# STM32WL5x_CM0P register map
File version: 1.5
CPU: CM0 r0p1, little endian, MPU, no FPU, 4 interrupt priority bits
Registers are 32-bit, read-write, reset 0x0 unless marked. A register's access mark holds for its fields unless they carry their own. Offsets are from the block's base; [hi:lo] are bit positions; {n}, {i} and the like mark numbered series; 'fields as' and 'values as' point back to an identical list.

## DMA1 — Direct memory access controller
Base 0x40020000
Same registers: DMA2 0x40020400
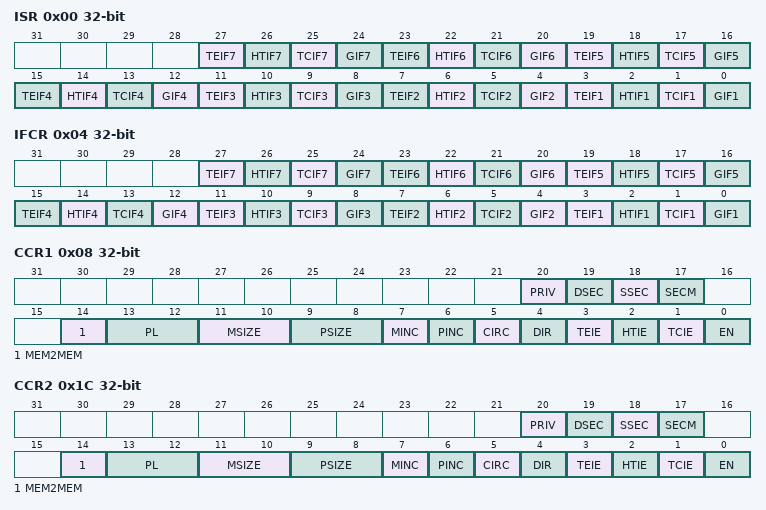
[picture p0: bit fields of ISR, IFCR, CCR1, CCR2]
0x00 ISR ro — interrupt status register
  [4n-1] TEIF{n} (n=1..7) — transfer error (TE) flag for channel {n}
  [4n-2] HTIF{n} (n=1..7) — half transfer (HT) flag for channel {n}
  [4n-3] TCIF{n} (n=1..7) — transfer complete (TC) flag for channel {n}
  [4n-4] GIF{n} (n=1..7) — global interrupt flag for channel {n}
0x04 IFCR wo — interrupt flag clear register
  [4n-1] TEIF{n} (n=1..7) — transfer error flag clear for channel {n}
  [4n-2] HTIF{n} (n=1..7) — half transfer flag clear for channel {n}
  [4n-3] TCIF{n} (n=1..7) — transfer complete flag clear for channel {n}
  [4n-4] GIF{n} (n=1..7) — global interrupt flag clear for channel {n}
0x08 CCR1 — channel x configuration register
  [20] PRIV — rivileged mode
  [19] DSEC — ecurity of the DMA transfer to the destination
  [18] SSEC — ecurity of the DMA transfer from the source
  [17] SECM — ecure mode
  [14] MEM2MEM — memory-to-memory mode
  [13:12] PL — priority level
  [11:10] MSIZE — memory size
  [9:8] PSIZE — peripheral size
  [7] MINC — memory increment mode
  [6] PINC — peripheral increment mode
  [5] CIRC — circular mode
  [4] DIR — data transfer direction
  [3] TEIE — transfer error interrupt enable
  [2] HTIE — half transfer interrupt enable
  [1] TCIE — transfer complete interrupt enable
  [0] EN — channel enable
0x0C CNDTR1 — channel x number of data to transfer register
  [17:0] NDT — number of data to transfer (0 to 218 - 1)
0x10 CPAR1 — channel x peripheral address register
  [31:0] PA — peripheral address
{0x0+0x14*i} CMAR{i} (i=1..7) — channel x memory address register
  [31:0] MA — peripheral address
0x1C CCR2 — channel x configuration register
  fields as CCR1
0x20 CNDTR2 — channel x number of data to transfer register
  [17:0] NDT — number of data to transfer (0 to 218 - 1)
0x24 CPAR2 — channel x peripheral address register
  [31:0] PA — peripheral address
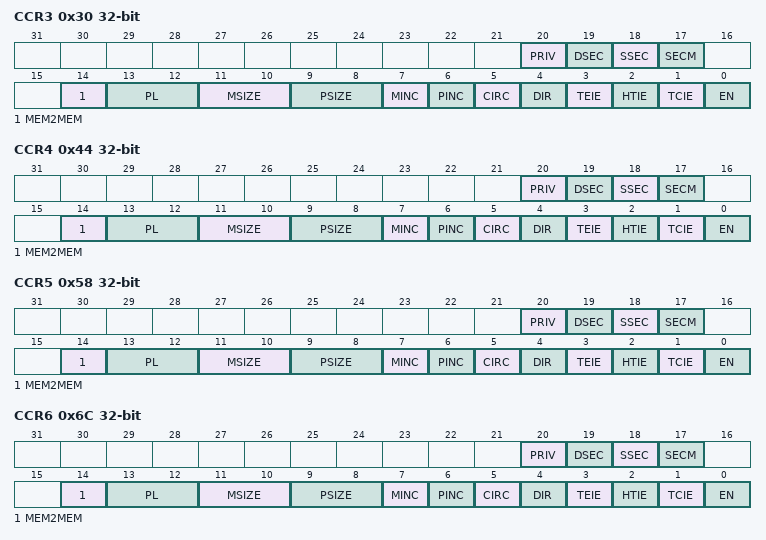
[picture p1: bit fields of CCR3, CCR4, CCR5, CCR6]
0x30 CCR3 — channel x configuration register
  fields as CCR1
0x34 CNDTR3 — channel x number of data to transfer register
  [17:0] NDT — number of data to transfer (0 to 218 - 1)
0x38 CPAR3 — channel x peripheral address register
  [31:0] PA — peripheral address
0x44 CCR4 — channel x configuration register
  fields as CCR1
0x48 CNDTR4 — channel x number of data to transfer register
  [17:0] NDT — number of data to transfer (0 to 218 - 1)
0x4C CPAR4 — channel x peripheral address register
  [31:0] PA — peripheral address
0x58 CCR5 — channel x configuration register
  fields as CCR1
0x5C CNDTR5 — channel x number of data to transfer register
  [17:0] NDT — number of data to transfer (0 to 218 - 1)
0x60 CPAR5 — channel x peripheral address register
  [31:0] PA — peripheral address
0x6C CCR6 — channel x configuration register
  fields as CCR1
0x70 CNDTR6 — channel x number of data to transfer register
  [17:0] NDT — number of data to transfer (0 to 218 - 1)
0x74 CPAR6 — channel x peripheral address register
  [31:0] PA — peripheral address
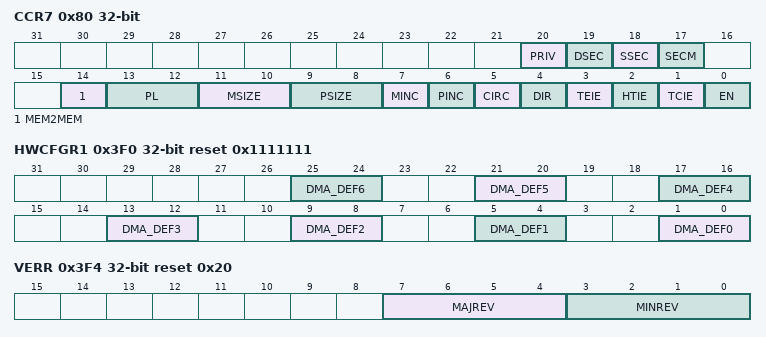
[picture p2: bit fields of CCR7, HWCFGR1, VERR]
0x80 CCR7 — channel x configuration register
  fields as CCR1
0x84 CNDTR7 — channel x number of data to transfer register
  [17:0] NDT — number of data to transfer (0 to 218 - 1)
0x88 CPAR7 — channel x peripheral address register
  [31:0] PA — peripheral address
0x98 CNDTR8 — channel x number of data to transfer register
  [17:0] NDT — number of data to transfer (0 to 218 - 1)
0x3EC HWCFGR2 reset 0x1 — hardware configuration register 2 [non-user]
  [1:0] TRUSTZONE — Security option
0x3F0 HWCFGR1 access per field reset 0x1111111 — hardware configuration register 1 [non-user]
  [4n+1:4n] DMA_DEF{n} rw (n=3..6) — channel {n+1} implementation parameter
  [9:8] DMA_DEF2 ro — channel 3 implementation parameter
  [5:4] DMA_DEF1 rw — channel 2 implementation parameter
  [1:0] DMA_DEF0 ro — channel 1 implementation parameter
0x3F4 VERR reset 0x20 — IP version register [non-user]
  [7:4] MAJREV — major peripheral revision
  [3:0] MINREV — minor peripheral revision
0x3F8 IPIDR ro reset 0x100001 — IP identification register [non-user]
  [31:0] ID — peripheral identification
0x3FC SIDR ro reset 0xA3C5DD01 — size identification register [non-user]
  [31:0] SID — size identification
